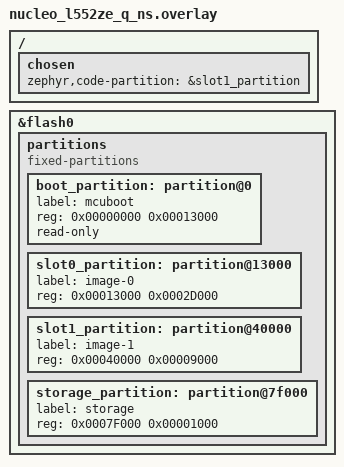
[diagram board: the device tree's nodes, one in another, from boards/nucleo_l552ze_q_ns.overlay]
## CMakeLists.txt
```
# SPDX-License-Identifier: Apache-2.0

cmake_minimum_required(VERSION 3.13.1)

find_package(Zephyr REQUIRED HINTS $ENV{ZEPHYR_BASE})

project(tfm_psa_level_1)

# Source files in this sample
target_sources(app PRIVATE src/main.c)
target_sources(app PRIVATE src/psa_attestation.c)
target_sources(app PRIVATE src/psa_crypto.c)
target_sources(app PRIVATE src/shell.c)
target_sources(app PRIVATE src/util_app_cfg.c)
target_sources(app PRIVATE src/util_app_log.c)
target_sources(app PRIVATE src/util_sformat.c)

target_include_directories(app PRIVATE
  ${ZEPHYR_TRUSTED_FIRMWARE_M_MODULE_DIR}/trusted-firmware-m/interface/include
)
```

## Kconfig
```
# Private config options for PSA level 1 application

# Copyright (c) 2019,2020 Linaro
# SPDX-License-Identifier: Apache-2.0

mainmenu "PSA level 1 sample application"

menu "Application configuration"

module = PSA
module-str = psa
source "subsys/logging/Kconfig.template.log_config"

endmenu

config PSA_SHELL
	bool "Enable the 'psa' shell command"
	depends on SHELL
	help
	  Enabling this option will make the 'psa' shell command available.

source "Kconfig.zephyr"
```

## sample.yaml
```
sample:
    description: This app provides an example of using TF-M on the secure
        side, with Zephyr on the NS side, using IPC mode.
    name: TF-M PSA Level 1 example
tests:
    sample.psa_level_1:
        tags: introduction tfm
        platform_allow: mps2_an521_nonsecure lpcxpresso55s69_ns nrf5340dk_nrf5340_cpuappns
          nrf9160dk_nrf9160ns nucleo_l552ze_q_ns v2m_musca_s1_nonsecure stm32l562e_dk_ns
          bl5340_dvk_cpuappns
        harness: console
        harness_config:
          type: multi_line
          regex:
            - "Creating new config file with UID"
            - "System IAT size is"
            - "Generating 256 bytes of random data"
```

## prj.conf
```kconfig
CONFIG_LOG=y
CONFIG_LOG_RUNTIME_FILTERING=y
CONFIG_LOG_BUFFER_SIZE=2048
CONFIG_LOG_PROCESS_TRIGGER_THRESHOLD=0
CONFIG_LOG_DEFAULT_LEVEL=4

#CONFIG_SHELL=n
#CONFIG_SHELL_HISTORY=y
#CONFIG_SHELL_VT100_COLORS=y
#CONFIG_SHELL_CMDS=n
#CONFIG_PSA_SHELL=y

CONFIG_BUILD_WITH_TFM=y

# The Zephyr CMSIS emulation assumes that ticks are ms, currently
CONFIG_SYS_CLOCK_TICKS_PER_SEC=1000

CONFIG_MAIN_STACK_SIZE=4096
CONFIG_HEAP_MEM_POOL_SIZE=4096
```

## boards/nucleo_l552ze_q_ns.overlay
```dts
/*
 * Copyright (c) 2020 Linaro Limited.
 *
 * SPDX-License-Identifier: Apache-2.0
 */


 /* This partition table should be used along with TFM configuration:
  * - TEST_S=OFF (NO REGRESSION)
  *
  * In this configuration, TFM binary does not include tests.
  * The partition sizes are compatible with the TF-M platform
  * flash_layout.h.
  */

  / {
	chosen {
		zephyr,code-partition = &slot1_partition;
	};
};

&flash0 {

	partitions {
		compatible = "fixed-partitions";
		#address-cells = <1>;
		#size-cells = <1>;

		boot_partition: partition@0 {
			label = "mcuboot";
			reg = <0x00000000 0x00013000>;
			read-only;
		};
		/* Secure image primary slot */
		slot0_partition: partition@13000 {
			label = "image-0";
			reg = <0x00013000 0x0002D000>;
		};
		/* Non-secure image primary slot */
		slot1_partition: partition@40000 {
			label = "image-1";
			reg = <0x00040000 0x00009000>;
		};
		/*
		 * The flash starting at 0x7F000 and ending at
		 * 0x80000 is reserved for the application.
		 */
		storage_partition: partition@7f000 {
			label = "storage";
			reg = <0x0007F000 0x00001000>;
		};
	};
};
```

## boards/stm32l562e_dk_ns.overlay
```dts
/*
 * Copyright (c) 2021 Yestin Sun
 *
 * SPDX-License-Identifier: Apache-2.0
 */

 /* This partition table should be used along with TFM configuration:
  * - TEST_S=OFF (NO REGRESSION)
  *
  * In this configuration, TFM binary does not include tests.
  * The partition sizes are compatible with the TF-M platform
  * flash_layout.h.
  */

/ {
	chosen {
		zephyr,code-partition = &slot1_partition;
	};
};

&flash0 {

	partitions {
		compatible = "fixed-partitions";
		#address-cells = <1>;
		#size-cells = <1>;

		boot_partition: partition@0 {
			label = "mcuboot";
			reg = <0x00000000 0x00019000>;
			read-only;
		};
		/* Secure image primary slot */
		slot0_partition: partition@19000 {
			label = "image-0";
			reg = <0x00019000 0x00038000>;
		};
		/* Non-secure image primary slot */
		slot1_partition: partition@51000 {
			label = "image-1";
			reg = <0x00051000 0x0002A000>;
		};
		/*
		 * The flash starting at 0x7F000 and ending at
		 * 0x80000 is reserved for the application.
		 */
		storage_partition: partition@7f000 {
			label = "storage";
			reg = <0x0007F000 0x00001000>;
		};
	};
};
```

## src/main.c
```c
/*
 * Copyright (c) 2019,2020 Linaro Limited
 *
 * SPDX-License-Identifier: Apache-2.0
 */

#include <zephyr.h>
#include <logging/log_ctrl.h>
#include <logging/log.h>

#include "tfm_ns_interface.h"
#include "psa_attestation.h"
#include "psa_crypto.h"
#include "util_app_cfg.h"
#include "util_app_log.h"
#include "util_sformat.h"

/** Declare a reference to the application logging interface. */
LOG_MODULE_DECLARE(app, CONFIG_LOG_DEFAULT_LEVEL);

/* Create an instance of the system config struct for the application. */
static struct cfg_data cfg;

void main(void)
{
	/* Initialise the logger subsys and dump the current buffer. */
	log_init();

	/* Load app config struct from secure storage (create if missing). */
	if (cfg_load_data(&cfg)) {
		LOG_ERR("Error loading/generating app config data in SS.");
	}

	/* Get the entity attestation token (requires ~1kB stack memory!). */
	att_test();

	/* Crypto tests */
	crp_test_rng();
	crp_test_sha256();

	/* Dump any queued log messages, and wait for system events. */
	while (1) {
		al_dump_log();
	}

	while (1) {

	}
}
```

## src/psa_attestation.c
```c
/*
 * Copyright (c) 2019,2020 Linaro Limited
 *
 * SPDX-License-Identifier: Apache-2.0
 */

#include <zephyr.h>
#include <stdio.h>
#include <logging/log.h>

#include "psa/initial_attestation.h"
#include "psa_attestation.h"
#include "util_app_log.h"
#include "util_sformat.h"

LOG_MODULE_DECLARE(app, CONFIG_LOG_DEFAULT_LEVEL);

psa_status_t att_get_pub_key(void)
{
	psa_status_t err = PSA_SUCCESS;

	/* TODO: How to retrieve this?!? */

	/* Log any eventual errors via app_log */
	return err ? al_psa_status(err, __func__) : err;
}

psa_status_t att_get_iat(uint8_t *ch_buffer, uint32_t ch_sz,
			 uint8_t *token_buffer, uint32_t *token_sz)
{
	psa_status_t err = PSA_SUCCESS;
	uint32_t sys_token_sz;
	size_t token_buf_size = ATT_MAX_TOKEN_SIZE;


	/* Call with with bigger challenge object than allowed */

	/*
	 * First determine how large the token is on this system.
	 * We don't need to compare with the size of ATT_MAX_TOKEN_SIZE here
	 * since a check will be made in 'psa_initial_attest_get_token' and the
	 * error return code will indicate a mismatch.
	 */
	switch (ch_sz) {
	case 32:
		err = psa_initial_attest_get_token(
			ch_buffer,
			PSA_INITIAL_ATTEST_CHALLENGE_SIZE_32,
			token_buffer,
			token_buf_size,
			&sys_token_sz);
		break;
	case 48:
		err = psa_initial_attest_get_token(
			ch_buffer,
			PSA_INITIAL_ATTEST_CHALLENGE_SIZE_48,
			token_buffer,
			token_buf_size,
			&sys_token_sz);
		break;
	case 64:
		err = psa_initial_attest_get_token(
			ch_buffer,
			PSA_INITIAL_ATTEST_CHALLENGE_SIZE_64,
			token_buffer,
			token_buf_size,
			&sys_token_sz);
		break;
	}
	LOG_INF("att: System IAT size is: %d bytes.", sys_token_sz);
	if (err) {
		goto err;
	}

	/* Request the initial attestation token w/the challenge data. */
	LOG_INF("att: Requesting IAT with %d byte challenge.", ch_sz);
	err = psa_initial_attest_get_token(
		ch_buffer,      /* Challenge/nonce input buffer. */
		ch_sz,          /* Challenge size (32, 48 or 64). */
		token_buffer,   /* Token output buffer. */
		token_buf_size,
		token_sz        /* Post exec output token size. */
		);
	LOG_INF("att: IAT data received: %d bytes.", *token_sz);

err:
	/* Log any eventual errors via app_log */
	return err ? al_psa_status(err, __func__) : err;
}

psa_status_t att_test(void)
{
	psa_status_t err = PSA_SUCCESS;

	/* 64-bytee nonce/challenge, encrypted using the default public key;
	 *
	 * 00 11 22 33 44 55 66 77 88 99 AA BB CC DD EE FF
	 * 00 11 22 33 44 55 66 77 88 99 AA BB CC DD EE FF
	 * 00 11 22 33 44 55 66 77 88 99 AA BB CC DD EE FF
	 * 00 11 22 33 44 55 66 77 88 99 AA BB CC DD EE FF
	 */
	uint32_t nonce_sz = 64;
	uint8_t nonce_buf[ATT_MAX_TOKEN_SIZE] = {
		0x00, 0x11, 0x22, 0x33, 0x44, 0x55, 0x66, 0x77,
		0x88, 0x99, 0xAA, 0xBB, 0xCC, 0xDD, 0xEE, 0xFF,
		0x00, 0x11, 0x22, 0x33, 0x44, 0x55, 0x66, 0x77,
		0x88, 0x99, 0xAA, 0xBB, 0xCC, 0xDD, 0xEE, 0xFF,
		0x00, 0x11, 0x22, 0x33, 0x44, 0x55, 0x66, 0x77,
		0x88, 0x99, 0xAA, 0xBB, 0xCC, 0xDD, 0xEE, 0xFF,
		0x00, 0x11, 0x22, 0x33, 0x44, 0x55, 0x66, 0x77,
		0x88, 0x99, 0xAA, 0xBB, 0xCC, 0xDD, 0xEE, 0xFF,
		0
	};

	/* IAT response buffer. */
	uint32_t iat_sz = ATT_MAX_TOKEN_SIZE;
	uint8_t iat_buf[ATT_MAX_TOKEN_SIZE] = { 0 };

	/* String format output config. */
	struct sf_hex_tbl_fmt fmt = {
		.ascii = true,
		.addr_label = true,
		.addr = 0
	};

	/* Request the IAT from the initial attestation service. */
	err = att_get_iat(nonce_buf, nonce_sz, iat_buf, &iat_sz);
	if (err) {
		goto err;
	}

	/* Display queued log messages before dumping the IAT. */
	al_dump_log();

	/* Dump the IAT for debug purposes. */
	sf_hex_tabulate_16(&fmt, iat_buf, (size_t)iat_sz);

err:
	return err;
}
```

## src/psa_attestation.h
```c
/*
 * Copyright (c) 2019,2020 Linaro Limited
 *
 * SPDX-License-Identifier: Apache-2.0
 */

#include <stdarg.h>

#include "psa/error.h"

#ifdef __cplusplus
extern "C" {
#endif

/** Maximum buffer size for an initial attestation token instance. */
#define ATT_MAX_TOKEN_SIZE (0x240)

/**
 * @brief Gets the public key portion of the attestation service's securely
 *        stored key pair. This public key can be provided to external
 *        verification services for device verification purposes.
 *
 * @return Returns error code as specified in \ref psa_status_t
 */
psa_status_t att_get_pub_key(void);

/**
 * @brief Gets an initial attestation token (IAT) from the TF-M secure
 *        processing environment (SPE). This data will be provided in CBOR
 *        format and is encrypted using the private key held on the SPE.
 *
 * The initial attestation token (IAT) is composed of a series of 'claims' or
 * data points used to uniquely identify this device to an external
 * verification entity (the IAT consumer).
 *
 * The generated IAT should be crytographically verrifiable by the IAT consumer.
 *
 * For details on IAT see https://tools.ietf.org/html/draft-mandyam-eat-01
 *
 * @param ch_buffer     Pointer to the buffer containing the nonce or
 *                      challenge data to be validated with the private key.
 * @param ch_sz         The number of bytes in the challenge. 32, 48 or 64.
 * @param token_buffer  Pointer to the buffer where the IAT will be written.
 *                      Must be equal in size to the system IAT output, which
 *                      can be determined via a call to
 *                      'psa_initial_attest_get_token_size'.
 * @param token_sz      Pointer to the size of token_buffer, this value will be
 *                      updated in this function to contain the number of bytes
 *                      actually retrieved during the IAT request.
 *
 * @return Returns error code as specified in \ref psa_status_t
 */
psa_status_t att_get_iat(uint8_t *ch_buffer, uint32_t ch_sz,
			 uint8_t *token_buffer, uint32_t *token_sz);

/**
 * @brief TODO!
 *
 * @return Returns error code as specified in \ref psa_status_t
 */
psa_status_t att_test(void);

#ifdef __cplusplus
}
#endif
```

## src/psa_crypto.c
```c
/*
 * Copyright (c) 2019,2020 Linaro Limited
 *
 * SPDX-License-Identifier: Apache-2.0
 */

#include <zephyr.h>
#include <logging/log_ctrl.h>
#include <logging/log.h>

#include "psa/crypto.h"
#include "psa_crypto.h"
#include "util_app_log.h"
#include "util_sformat.h"

/** Declare a reference to the application logging interface. */
LOG_MODULE_DECLARE(app, CONFIG_LOG_DEFAULT_LEVEL);

/**
 * @brief Generates random values using the TF-M crypto service.
 */
void crp_test_rng(void)
{
	psa_status_t status;
	uint8_t outbuf[256] = { 0 };
	struct sf_hex_tbl_fmt fmt = {
		.ascii = true,
		.addr_label = true,
		.addr = 0
	};

	status = al_psa_status(psa_generate_random(outbuf, 256), __func__);
	LOG_INF("Generating 256 bytes of random data.");
	al_dump_log();
	sf_hex_tabulate_16(&fmt, outbuf, 256);
}

/**
 * @brief Demonstrates how to calcute the SHA-256 hash of a value in chunks.
 */
void crp_test_sha256(void)
{
	const psa_algorithm_t alg = PSA_ALG_SHA_256;
	static const char *const msg[] = { "This is my test message, ",
					   "please generate a hash for this." };
	const size_t msg_size[] = { 25, 32 };
	uint8_t hash_val[PSA_HASH_SIZE(PSA_ALG_SHA_256)] = { 0 };
	size_t hash_len;
	const uint32_t msg_num = ARRAY_SIZE(msg) / sizeof(msg[0]);
	uint32_t idx;
	psa_status_t status;
	psa_hash_operation_t handle = psa_hash_operation_init();

	LOG_INF("Calculating SHA-256 hash of value.");
	al_dump_log();

	/* Setup the hash object. */
	status = al_psa_status(psa_hash_setup(&handle, alg), __func__);
	if (status != PSA_SUCCESS) {
		goto err;
	}

	/* Update object with all the message chunks. */
	for (idx = 0; idx < msg_num; idx++) {
		status = al_psa_status(
			psa_hash_update(
				&handle,
				(const uint8_t *)msg[idx], msg_size[idx]),
			__func__);
		if (status != PSA_SUCCESS) {
			goto err;
		}
	}

	/* Finalize the hash calculation. */
	status = al_psa_status(
		psa_hash_finish(&handle,
				hash_val,
				sizeof(hash_val),
				&hash_len),
		__func__);
	if (status != PSA_SUCCESS) {
		goto err;
	}

	/* Display the SHA-256 hash for debug purposes */
	struct sf_hex_tbl_fmt fmt = {
		.ascii = false,
		.addr_label = true,
		.addr = 0
	};
	sf_hex_tabulate_16(&fmt, hash_val, (size_t)(PSA_HASH_SIZE(alg)));

	return;
err:
	psa_hash_abort(&handle);
	al_dump_log();
}
```

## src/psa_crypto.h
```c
/*
 * Copyright (c) 2019,2020 Linaro Limited
 *
 * SPDX-License-Identifier: Apache-2.0
 */

#include <zephyr.h>

#include "psa/error.h"

#ifdef __cplusplus
extern "C" {
#endif

void crp_test_rng(void);
void crp_test_sha256(void);

#ifdef __cplusplus
}
#endif
```

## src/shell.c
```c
/*
 * Copyright (c) 2019,2020 Linaro Limited
 *
 * SPDX-License-Identifier: Apache-2.0
 */

#include <stdlib.h>
#include <ctype.h>
#include <shell/shell.h>

#if CONFIG_PSA_SHELL

static int
psa_shell_invalid_arg(const struct shell *shell, char *arg_name)
{
	shell_print(shell, "Error: invalid argument \"%s\"\n", arg_name);

	return -EINVAL;
}

static int
psa_shell_cmd_version(const struct shell *shell, size_t argc, char **argv)
{
	shell_print(shell, "%s", "0.0.0");

	return 0;
}

/* Subcommand array for "psa" (level 1). */
SHELL_STATIC_SUBCMD_SET_CREATE(sub_psa,
	/* 'version' command handler. */
	SHELL_CMD(version, NULL, "app version", psa_shell_cmd_version),
	/* Array terminator. */
	SHELL_SUBCMD_SET_END
);

/* Root command "psa" (level 0). */
SHELL_CMD_REGISTER(psa, &sub_psa, "PSA commands", NULL);

#endif
```

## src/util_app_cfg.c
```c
/*
 * Copyright (c) 2019,2020 Linaro Limited
 *
 * SPDX-License-Identifier: Apache-2.0
 */

#include <string.h>
#include <logging/log.h>

#include "psa/error.h"
#include "psa/protected_storage.h"
#include "util_app_cfg.h"
#include "util_app_log.h"

/** The 64-bit UID associated with the config record in secure storage. */
static psa_storage_uid_t cfg_data_uid = 0x0000000055CFDA7A;

LOG_MODULE_DECLARE(app, CONFIG_LOG_DEFAULT_LEVEL);

/**
 * @brief Default config settings. These settings will be used when a new
 *        config record is created, or when the config record is reset.
 */
static struct cfg_data cfg_data_dflt = {
	.magic = 0x55CFDA7A,
	.version = 1,
	.scratch = { 0 }
};

psa_status_t cfg_create_data(void)
{
	psa_status_t status;

	LOG_INF("app_cfg: Creating new config file with UID 0x%llX",
		(uint64_t)cfg_data_uid);

	/*
	 * psa_ps_create can also be used here, which enables to the use of
	 * the psa_ps_set_extended function, but this requires us to set a
	 * maximum file size for resource allocation. Since the upper limit
	 * isn't known at present, we opt here for the simpler psa_ps_set
	 * call which also creates the secure storage record if necessary,
	 * but precludes the use of psa_ps_set_extended.
	 */
	status = psa_ps_set(cfg_data_uid, sizeof(cfg_data_dflt),
			    (void *)&cfg_data_dflt, 0);
	if (status) {
		goto err;
	}

err:
	return (status ? al_psa_status(status, __func__) : status);
}

psa_status_t cfg_load_data(struct cfg_data *p_cfg_data)
{
	psa_status_t status;
	struct psa_storage_info_t p_info;

	memset(&p_info, 0, sizeof(p_info));

	/* Check if the config record exists, if not create it. */
	status = psa_ps_get_info(cfg_data_uid, &p_info);
	if (status == PSA_ERROR_DOES_NOT_EXIST) {
		/* Create a new config file. */
		status = cfg_create_data();
		/* Copy default values to the cfg_data placeholder. */
		memcpy(p_cfg_data, &cfg_data_dflt, sizeof(cfg_data_dflt));
	}
	if (status) {
		goto err;
	}

err:
	return (status ? al_psa_status(status, __func__) : status);
}
```

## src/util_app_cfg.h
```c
/*
 * Copyright (c) 2019,2020 Linaro Limited
 *
 * SPDX-License-Identifier: Apache-2.0
 */

#include <zephyr.h>

#include "psa/error.h"

#ifdef __cplusplus
extern "C" {
#endif

/**
 * @brief The struct used to persist config data to secure storage.
 *
 * The first 6 bytes of this struct should remain consistent in any future
 * firmware updates, since they can be used to identify to layout of the rest
 * of the struct in cases where config data version management becomes
 * a necessity.
 */
struct cfg_data {
	/**
	 * @brief Magic number for config data payloads (0x55CFDA7A).
	 */
	uint32_t magic;

	/**
	 * @brief The version number for the stored config record.
	 *
	 * This number should be incremented any time the config_data struct
	 * definition changes to allow version management of config data at
	 * the application level.
	 */
	uint16_t version;

	/** @brief 256-byte debug scratch area. */
	uint8_t scratch[256];
};

/**
 * @brief Creates a new config record in secure storage.
 *
 * @return #PSA_SUCCESS on success, otherwise a appropriate psa_status_t code.
 */
psa_status_t cfg_create_data(void);

/**
 * @brief Attempts to loac the config record from secure storage. If the
 *        record is not found in secure storage, a new record will be created
 *        using default config settings.
 *
 * @param p_cfg_data Pointer to the cfg_data struct where the config data
 *        should be assigned once loaded.
 *
 * @return #PSA_SUCCESS on success, otherwise a appropriate psa_status_t code.
 */
psa_status_t cfg_load_data(struct cfg_data *p_cfg_data);

#ifdef __cplusplus
}
#endif
```

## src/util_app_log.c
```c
/*
 * Copyright (c) 2019,2020 Linaro Limited
 *
 * SPDX-License-Identifier: Apache-2.0
 */
#include <zephyr.h>
#include <logging/log_ctrl.h>
#include <logging/log.h>

#include "psa/crypto.h"
#include "util_app_log.h"

LOG_MODULE_REGISTER(app, CONFIG_LOG_DEFAULT_LEVEL);

psa_status_t al_psa_status(psa_status_t status, const char *func_name)
{
	switch (status) {
	case PSA_SUCCESS:
		break;

	/* Generic PSA errors (psa/error.h). */
	case PSA_ERROR_PROGRAMMER_ERROR:
		LOG_ERR("Programmer error");
		break;
	case PSA_ERROR_CONNECTION_REFUSED:
		LOG_ERR("Connection refused");
		break;
	case PSA_ERROR_CONNECTION_BUSY:
		LOG_ERR("Connection busy");
		break;
	case PSA_ERROR_GENERIC_ERROR:
		LOG_ERR("Generic error");
		break;
	case PSA_ERROR_NOT_PERMITTED:
		LOG_ERR("Not permitted");
		break;
	case PSA_ERROR_NOT_SUPPORTED:
		LOG_ERR("Unsupported operation");
		break;
	case PSA_ERROR_INVALID_ARGUMENT:
		LOG_ERR("Invalid argument");
		break;
	case PSA_ERROR_INVALID_HANDLE:
		LOG_ERR("Invalid handle");
		break;
	case PSA_ERROR_BAD_STATE:
		LOG_ERR("Bad state");
		break;
	case PSA_ERROR_BUFFER_TOO_SMALL:
		LOG_ERR("Buffer too small");
		break;
	case PSA_ERROR_ALREADY_EXISTS:
		LOG_ERR("Already exists");
		break;
	case PSA_ERROR_DOES_NOT_EXIST:
		LOG_ERR("Does not exist");
		break;
	case PSA_ERROR_INSUFFICIENT_MEMORY:
		LOG_ERR("Insufficient memory");
		break;
	case PSA_ERROR_INSUFFICIENT_STORAGE:
		LOG_ERR("Insufficient storage");
		break;
	case PSA_ERROR_INSUFFICIENT_DATA:
		LOG_ERR("Insufficient memory data");
		break;
	case PSA_ERROR_SERVICE_FAILURE:
		LOG_ERR("Service failure");
		break;
	case PSA_ERROR_COMMUNICATION_FAILURE:
		LOG_ERR("Communication failure");
		break;
	case PSA_ERROR_STORAGE_FAILURE:
		LOG_ERR("Storage failure");
		break;
	case PSA_ERROR_HARDWARE_FAILURE:
		LOG_ERR("Hardware failure");
		break;
	case PSA_ERROR_INVALID_SIGNATURE:
		LOG_ERR("Invalid signature");
		break;

	/* PSA crypto errors (psa/crypto_values.h). */
	case PSA_ERROR_INSUFFICIENT_ENTROPY:
		LOG_ERR("CRYPTO: Insufficient entropy");
		break;
	case PSA_ERROR_TAMPERING_DETECTED:
		LOG_ERR("CRYPTO: Tampering detected");
		break;

	/* Catch-all error handler. */
	default:
		LOG_ERR("Unhandled status response: %d", status);
		break;
	}

	/* Display the calling function name for debug purposes. */
	if (status != PSA_SUCCESS) {
		LOG_ERR("Function: '%s'", func_name);
	}

	return status;
}

void al_dump_log(void)
{
	while (log_process(false)) {

	}
}
```

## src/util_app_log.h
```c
/*
 * Copyright (c) 2019,2020 Linaro Limited
 *
 * SPDX-License-Identifier: Apache-2.0
 */

#include <stdarg.h>

#include "psa/error.h"
#include "psa/initial_attestation.h"
#include "psa/protected_storage.h"

#ifdef __cplusplus
extern "C" {
#endif

/**
 * @brief Logs PSA response messages other than PSA_SUCCESS for debugging
 *        purposes.
 *
 * @param status        The psa_status_t value to log.
 * @param func_name     The name of the function that made this function call.
 *
 * @return Returns the psa_status_t value passed into the function.
 */
psa_status_t al_psa_status(psa_status_t status, const char *func_name);

/**
 * @brief Calls 'log_process' in Zephyr to dump any queued log messages.
 */
void al_dump_log(void);

#ifdef __cplusplus
}
#endif
```

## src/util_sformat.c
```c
/*
 * Copyright (c) 2019,2020 Linaro Limited
 *
 * SPDX-License-Identifier: Apache-2.0
 */

#include <ctype.h>
#include <stdio.h>
#include "util_sformat.h"

static void sf_hex_ascii(unsigned char *data, size_t len, unsigned char nonvis)
{
	uint32_t idx;

	/* Render printable characters. */
	idx = 0;
	while (len) {
		printf("%c", isprint(data[idx]) ? data[idx] : nonvis);
		idx++;
		len--;
	}
}

void sf_hex_tabulate_16(struct sf_hex_tbl_fmt *fmt, unsigned char *data,
			size_t len)
{
	uint32_t idx;
	uint32_t cpos;     /* Current position. */
	uint32_t ca;       /* Current address. */
	uint32_t ea;       /* End address. */

	if (!len) {
		return;
	}

	/* Set the end address (since we modify len in the write loop). */
	ea = fmt->addr + len;

	/* Check if we need to render the top address bar. */
	if (fmt->addr_label) {
		/* Render the top address bar. */
		printf("          ");
		printf("0  1  2  3  4  5  6  7  8  9  ");
		printf("A  B  C  D  E  F\n");
		printf("%08X ", fmt->addr - (fmt->addr % 16));
	}

	/* Insert offset padding for first row if necessary. */
	cpos = fmt->addr % 16;
	if (cpos != 0) {
		for (idx = 0; idx < cpos; idx++) {
			printf("   ");
		}
	}

	/* Print data row by row. */
	idx = 0;
	ca = fmt->addr;
	while (len) {
		/* Print the current value. */
		printf("%02X ", data[idx++]);
		cpos++;
		ca++;

		/* Wrap around to the next line if necessary. */
		if (cpos == 16 || ca == ea) {
			/* Render ASCII equiv at end of row if requested. */
			if (fmt->ascii) {
				if (ca == ea) {
					/* Handle last/single row. */
					if (ca % 16) {
						/* PARTIAL row (< 16 vals). */
						printf("%.*s",
						       (16 - ca % 16) * 3,
						       "                "
						       "                "
						       "                ");
						sf_hex_ascii(
							&data[idx - (ca % 16)],
							ca - fmt->addr < 16 ?
							idx % 16 : ca % 16,
							'.');
					} else {
						/* FULL row. */
						sf_hex_ascii(
							&data[idx - 16],
							16, '.');
					}
				} else if (ca < fmt->addr + 15) {
					/* Handle first row. */
					printf("%.*s", fmt->addr % 16,
					       "                ");
					sf_hex_ascii(data,
						     16 - fmt->addr % 16, '.');
				} else {
					/* Full row. */
					sf_hex_ascii(&data[idx - 16], 16, '.');
				}
			}

			/* Wrap around if this isn't the last row. */
			printf("\n");
			if (ca != ea) {
				/* Render the next base row addr. */
				if (fmt->addr_label) {
					printf("%08X ", ca);
				}
			}
			cpos = 0;
		}
		len--;
	}
}
```

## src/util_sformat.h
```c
/*
 * Copyright (c) 2019,2020 Linaro Limited
 *
 * SPDX-License-Identifier: Apache-2.0
 */

#ifndef _SFORMAT_H_
#define _SFORMAT_H_

#include <stdint.h>
#include <zephyr.h>

#ifdef __cplusplus
extern "C" {
#endif

/**
 * @brief Indicates how hex data should be rendered in tabular format.
 */
struct sf_hex_tbl_fmt {
	/** Whether or not to render ASCII equivalents. */
	uint8_t ascii : 1;
	/** Whether or not to add address labels to the output. */
	uint8_t addr_label : 1;
	/** The starting value for the address labels. */
	uint32_t addr;
} __packed;

/**
 * @brief Prints a 16-value wide tabular rendering of 8-bit hex data, with
 *        optional ascii equivalents and address labels.
 *
 * @param fmt   Pointer to thee sf_hex_tbl_fmt struct indicating how the
 *              table should be rendered.
 * @param data  Pointer to the data to render.
 * @param len   The number of bytes to render from data.
 */
void sf_hex_tabulate_16(struct sf_hex_tbl_fmt *fmt, unsigned char *data,
			size_t len);

#ifdef __cplusplus
}
#endif

#endif /* _SFORMAT_H_ */
```
